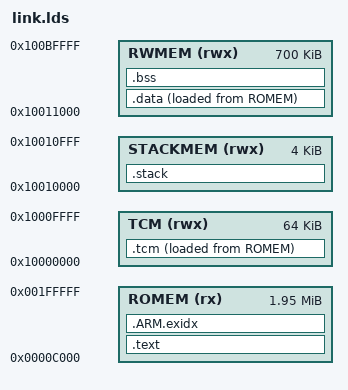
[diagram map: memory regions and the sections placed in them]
/******************************************************************************
 *
 * linker_script.ld - Linker script for applications using startup_gnu.c
 *
 *****************************************************************************/
ENTRY(Reset_Handler)

MEMORY
{
    ROMEM (rx) : ORIGIN = 0x0000C000, LENGTH = 2048000
    RWMEM (rwx) : ORIGIN = 0x10011000, LENGTH = 716800
    TCM (rwx) : ORIGIN = 0x10000000, LENGTH = 65536
    STACKMEM (rwx) : ORIGIN = 0x10010000, LENGTH = 4096
}

SECTIONS
{
    .text :
    {
        . = ALIGN(4);
        KEEP(*(.isr_vector))
        KEEP(*(.patch))
        *(.text)
        *(.text*)
        *(.rodata)
        *(.rodata*)
        /* section information for finsh shell */
        . = ALIGN(4);
        __fsymtab_start = .;
        KEEP(*(FSymTab))
        __fsymtab_end = .;

        . = ALIGN(4);
        __vsymtab_start = .;
        KEEP(*(VSymTab))
        __vsymtab_end = .;

        /* section information for initial. */
        . = ALIGN(4);
        __rt_init_start = .;
        KEEP(*(SORT(.rti_fn*)))
        __rt_init_end = .;

        . = ALIGN(4);
        PROVIDE(__ctors_start__ = .);
        KEEP (*(SORT(.init_array.*)))
        KEEP (*(.init_array))
        PROVIDE(__ctors_end__ = .);

        . = ALIGN(4);
        _etext = .;
    } > ROMEM

    /* .ARM.exidx is sorted, so has to go in its own output section.  */
    __exidx_start = .;
    .ARM.exidx :
    {
        *(.ARM.exidx* .gnu.linkonce.armexidx.*)

        /* This is used by the startup in order to initialize the .data secion */
        _sidata = .;
    } > ROMEM
    __exidx_end = .;

    .data :
    {
        . = ALIGN(4);
        _sdata = .;
        *(.data)
        *(.data*)
        . = ALIGN(4);
        _edata = .;
    } > RWMEM AT>ROMEM

    /* used by startup to initialize data */
    _init_data = LOADADDR(.data);

    .tcm :
    {
        . = ALIGN(4);
        _stcm = .;
        *(.tcm)
        *(.tcm*)
        . = ALIGN(4);
        _etcm = .;
    } > TCM AT>ROMEM

    /* used by startup to initialize tcm */
    _init_tcm = LOADADDR(.tcm);

    /* User stack section initialized by startup code. */
    .stack (NOLOAD):
    {
        . = ALIGN(8);
        *(.stack)
        *(.stack*)
        . = ALIGN(8);
    } > STACKMEM

    .bss :
    {
        . = ALIGN(4);
        _sbss = .;
        *(.bss)
        *(.bss*)
        *(COMMON)
        . = ALIGN(4);
        _ebss = .;
    } > RWMEM

    .ARM.attributes 0 : { *(.ARM.attributes) }
}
